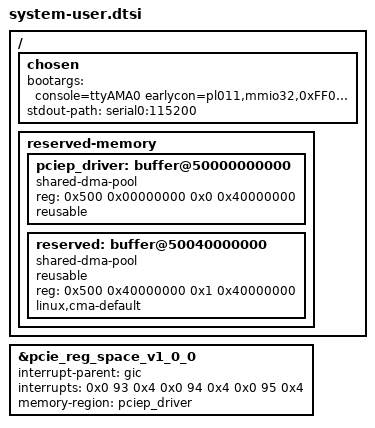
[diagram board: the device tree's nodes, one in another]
/include/ "system-conf.dtsi"
/include/ "pcie.dtsi"
/ {
	chosen {
		 bootargs = "console=ttyAMA0 earlycon=pl011,mmio32,0xFF000000,115200n8 clk_ignore_unused root=/dev/mmcblk0p2 rw rootwait";
		stdout-path = "serial0:115200";
	};
	reserved-memory {
		 #address-cells = <2>;
		 #size-cells = <2>;
		 ranges;
		pciep_driver: buffer@50000000000 {
	 		compatible = "shared-dma-pool";
                	reg = <0x500 0x00000000 0x0 0x40000000>;
                	reusable;
			};
		reserved: buffer@50040000000 {
		        compatible = "shared-dma-pool";
			reusable;
		        reg = <0x500 0x40000000 0x1 0x40000000>;
		        linux,cma-default;
		        };
		};
};
&pcie_reg_space_v1_0_0 {
    interrupt-parent = <&gic>;
    interrupts = <0x0 93 0x4 0x0 94 0x4 0x0 95 0x4 >;
    interrupt-names = "read", "write", "close";
    memory-region = <&pciep_driver>;
};
#include "pl-custom.dtsi"
